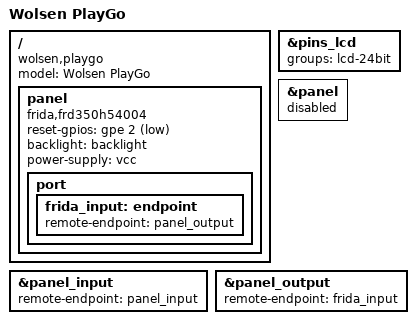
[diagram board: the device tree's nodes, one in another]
// SPDX-License-Identifier: GPL-2.0
/dts-v1/;

#include "rg280m.dts"

/ {
	compatible = "wolsen,playgo", "ingenic,jz4770";
	model = "Wolsen PlayGo";

	panel {
		compatible = "frida,frd350h54004";

		reset-gpios = <&gpe 2 GPIO_ACTIVE_LOW>;

		backlight = <&backlight>;
		power-supply = <&vcc>;

		port {
			frida_input: endpoint {
				remote-endpoint = <&panel_output>;
			};
		};
	};
};

&pins_lcd {
	groups = "lcd-24bit";
};

&panel {
	status = "disabled";
};

/* Make ABT panel port a dummy to avoid DTC complaints */
&panel_input {
	remote-endpoint = <&panel_input>;
};

&panel_output {
	remote-endpoint = <&frida_input>;
};
